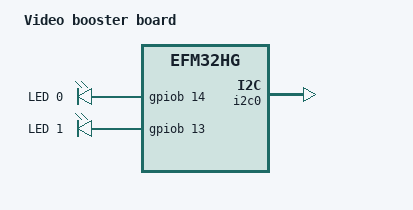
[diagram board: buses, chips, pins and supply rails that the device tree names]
/*
 * Copyright (c) 2020 Antmicro
 *
 * SPDX-License-Identifier: Apache-2.0
 */

/dts-v1/;
#include <silabs/efm32hg322f64.dtsi>

/ {
	model = "Video booster board";
	compatible = "video_booster", "silabs,efm32hg";

	chosen {
		zephyr,sram = &sram0;
		zephyr,flash = &flash0;
	};

        aliases {
                led0 = &led0;
                led1 = &led1;
        };

        leds {
                compatible = "gpio-leds";
                led0: led_0 {
                        gpios = <&gpiob 14 0>;
                        label = "LED 0";
                };

                led1: led_1 {
                        gpios = <&gpiob 13 0>;
                        label = "LED 1";
                };
        };
};


&cpu0 {
	clock-frequency = <20000000>;
};

&flash0 {
	/*
	 * For more information, see:
	 * http://docs.zephyrproject.org/latest/guides/dts/index.html#flash-partitions
	 */
	partitions {
		compatible = "fixed-partitions";
		#address-cells = <1>;
		#size-cells = <1>;

		/* Set 4Kb of storage at the end of the 64Kb of flash */
		storage_partition: partition@f000 {
			label = "storage";
			reg = <0x0000f000 0x00001000>;
		};

	};
};

&i2c0 {
        location-sda = <GECKO_LOCATION(6) GECKO_PORT_E GECKO_PIN(12)>;
        location-scl = <GECKO_LOCATION(6) GECKO_PORT_E GECKO_PIN(13)>;
	status = "okay";
};
